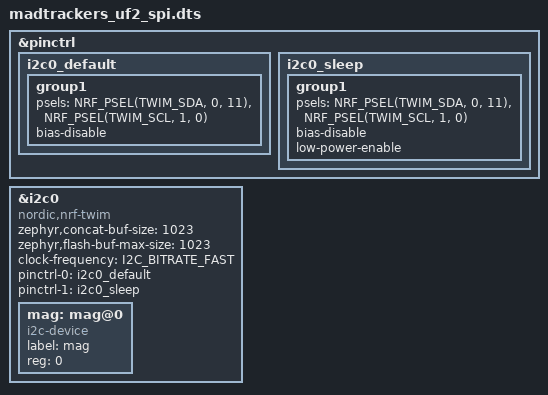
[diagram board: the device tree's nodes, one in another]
// Copyright (c) 2024 Nordic Semiconductor ASA
// SPDX-License-Identifier: Apache-2.0

/dts-v1/;
#include "madtrackers_uf2.dts"

&pinctrl {
	i2c0_default: i2c0_default {
		group1 {
			psels = <NRF_PSEL(TWIM_SDA, 0, 11)>, <NRF_PSEL(TWIM_SCL, 1, 0)>;
			bias-disable;
		};
	};

	i2c0_sleep: i2c0_sleep {
		group1 {
			psels = <NRF_PSEL(TWIM_SDA, 0, 11)>, <NRF_PSEL(TWIM_SCL, 1, 0)>;
			bias-disable;
			low-power-enable;
		};
	};
};

&i2c0 {
	compatible = "nordic,nrf-twim";
	status = "okay";
	zephyr,concat-buf-size = <1023>;
	zephyr,flash-buf-max-size = <1023>;
	clock-frequency = <I2C_BITRATE_FAST>;
	pinctrl-0 = <&i2c0_default>;
	pinctrl-1 = <&i2c0_sleep>;
	pinctrl-names = "default", "sleep";

	/delete-node/ imu;

	mag: mag@0 {
		compatible = "i2c-device";
		label = "mag";
		reg = <0>;
	};
};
